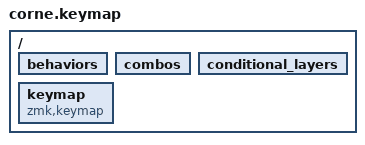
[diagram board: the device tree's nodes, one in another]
// Copyright (c) 2022 The ZMK Contributors
// SPDX-License-Identifier: MIT
//
// THIS IS A FRENCH LAYOUT MAPPING

#include <behaviors.dtsi>
#include <dt-bindings/zmk/keys.h>
#include <dt-bindings/zmk/bt.h>


/*
 * Here is a translation for all the French keys (AZERTY layout)
 */

#define FR_SUP2 GRAVE        // ²
#define FR_AMPR N1           // &
#define FR_EACU N2           // é
#define FR_DQT N3            // "
#define FR_SQT N4            // '
#define FR_LPAR N5           // (
#define FR_MINUS N6          // -
#define FR_EGRV N7           // è
#define FR_UNDS N8           // _
#define FR_CCED N9           // ç
#define FR_AGRV N0           // à
#define FR_RPAR MINUS        // )
#define FR_EQUAL EQUAL       // =
#define FR_A Q               // A
#define FR_Z W               // Z
#define FR_E E               // E
#define FR_R R               // R
#define FR_T T               // T
#define FR_Y Y               // Y
#define FR_U U               // U
#define FR_I I               // I
#define FR_O O               // O
#define FR_P P               // P
#define FR_CIRC LBKT         // ^
#define FR_DLR RBKT          // $
#define FR_Q A               // Q
#define FR_S S               // S
#define FR_D D               // D
#define FR_F F               // F
#define FR_G G               // G
#define FR_H H               // H
#define FR_J J               // J
#define FR_K K               // K
#define FR_L L               // L
#define FR_M SEMI            // M
#define FR_UGRV SQT          // ù
#define FR_AST NUHS          // *
#define FR_LT NUBS           // <
#define FR_W Z               // W
#define FR_X X               // X
#define FR_C C               // C
#define FR_V V               // V
#define FR_B B               // B
#define FR_N N               // N
#define FR_COMMA M           // .
#define FR_SEMI COMMA        // ;
#define FR_COLON DOT         // :
#define FR_EXCL FSLH         // !
#define FR_1 LS(FR_AMPR)     // 1
#define FR_2 LS(FR_EACU)     // 2
#define FR_3 LS(FR_DQT)      // 3
#define FR_4 LS(FR_SQT)      // 4
#define FR_5 LS(FR_LPAR)     // 5
#define FR_6 LS(FR_MINUS)    // 6
#define FR_7 LS(FR_EGRV)     // 7
#define FR_8 LS(FR_UNDS)     // 8
#define FR_9 LS(FR_CCED)     // 9
#define FR_0 LS(FR_AGRV)     // 0
#define FR_DEG LS(FR_RPAR)   // °
#define FR_PLUS LS(FR_EQUAL) // +
#define FR_DIAE LS(FR_CIRC)  // ¨
#define FR_PND  LS(FR_DLR)   // £
#define FR_PERC LS(FR_UGRV)  // %
#define FR_MICR LS(FR_AST)   // µ
#define FR_GT LS(FR_LT)      // >
#define FR_QUES LS(FR_COMMA) // ?
#define FR_DOT  LS(FR_SEMI)  // .
#define FR_SLSH LS(FR_COLON) // /
#define FR_SECT LS(FR_EXCL)  // §
#define FR_TILD RA(FR_EACU)  // ~
#define FR_HASH RA(FR_DQT)   // #
#define FR_LBRC RA(FR_SQT)   // {
#define FR_LBRK RA(FR_LPAR)  // [
#define FR_PIPE RA(FR_MINUS) // |
#define FR_GRV  RA(FR_EGRV)  // `
#define FR_BSLS RA(FR_UNDS)  // (backslash)
#define FR_AT   RA(FR_AGRV)  // @
#define FR_RBRK RA(FR_RPAR)  // ]
#define FR_RBRC RA(FR_EQUAL) // }
#define FR_EURO RA(E)        // €
#define FR_CURR RA(FR_DLR)   // ¤


// Home row mods macro
/*
HRML(k1,k2,k3,k4) maps to:
- k1 with Left Shift when held
- k2 with Left Alt when held
- k3 with Left Control when held
- k4 with Left GUI (Windows/Command) when held
*/
#define HRML(k1,k2,k3,k4) &ht LSHIFT k1 &ht LALT k2  &ht LCTRL k3  &ht LGUI k4

/*
HRMR(k1,k2,k3,k4) maps to:
- k1 with Right GUI when held
- k2 with Right Control when held
- k3 with Right Alt when held
- k4 with Right Shift when held
*/
#define HRMR(k1,k2,k3,k4) &ht RGUI k1  &ht RCTRL k2  &ht RALT k3 &ht RSHIFT k4

// Right Shift + Alt Gr
#define RSA(k) RS(RA(k))

// Layers name
#define BAZ 0
#define RIG 1
#define LEF 2
#define TRI 3
#define MOUSE 4


// Mouse settings
#define ZMK_POINTING_DEFAULT_MOVE_VAL 600  // default: 600
#define ZMK_POINTING_DEFAULT_SCRL_VAL 10    // default: 10
#include <dt-bindings/zmk/pointing.h>


/ {
    behaviors {
        #include "common/layers/behaviours.dtsi"
    };

    combos {
        #include "layouts/optimot/layers/combos.dtsi"
    };

    conditional_layers {
        #include "common/layers/conditional.dtsi"
    };

    keymap {
        compatible = "zmk,keymap";
        #include "layouts/optimot/layers/default.dtsi"
        #include "layouts/optimot/layers/right.dtsi"
        #include "layouts/optimot/layers/left.dtsi"
        #include "common/layers/tri.dtsi"
        #include "common/layers/mouse.dtsi"
    };
};
